# STM32F405 register map
STM32F405 (Cortex-M4F): RCC, GPIOA and USART1
CPU: CM4, FPU
Registers are 32-bit, access not given, no defined reset value unless marked. A register's access mark holds for its fields unless they carry their own. Offsets are from the block's base; lines under a group give offsets from that group; [hi:lo] are bit positions; {n}, {i} and the like mark numbered series; 'fields as' and 'values as' point back to an identical list; <NAME> marks a mode.

## Memory map
0x40011000 USART1 — Universal synchronous asynchronous receiver transmitter
0x40020000 GPIOA — General-purpose I/Os
0x40023800 RCC — Reset and clock control

## Interrupts
37 USART1 — USART1 global interrupt

## RCC — Reset and clock control
Base 0x40023800
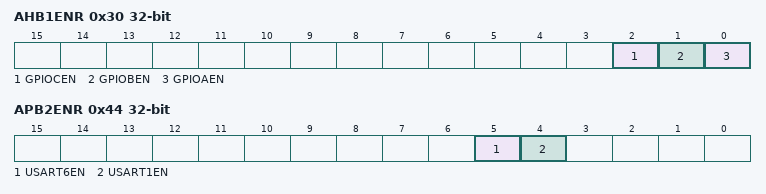
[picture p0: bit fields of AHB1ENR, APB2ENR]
0x30 AHB1ENR — AHB1 peripheral clock enable register
  [2] GPIOCEN — IO port C clock enable
  [1] GPIOBEN — IO port B clock enable
  [0] GPIOAEN — IO port A clock enable
0x44 APB2ENR — APB2 peripheral clock enable register
  [5] USART6EN — USART6 clock enable
  [4] USART1EN — USART1 clock enable

## GPIOA — General-purpose I/Os
Base 0x40020000
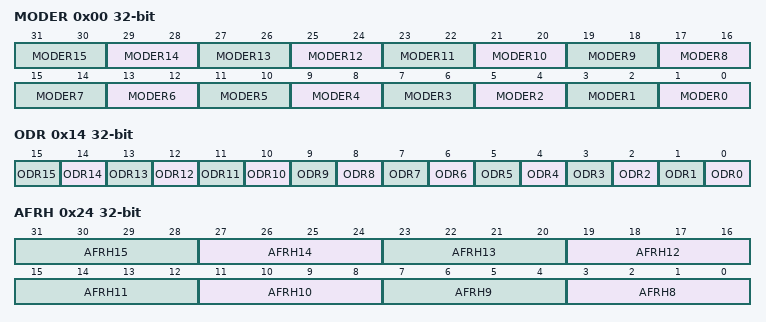
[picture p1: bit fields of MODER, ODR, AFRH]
0x00 MODER — GPIO port mode register: 0 input, 1 output, 2 alternate function, 3 analog
  [2n+1:2n] MODER{n} (n=0..15) — Port x configuration
0x14 ODR — GPIO port output data register
  [n] ODR{n} (n=0..15) — Port output data
0x24 AFRH — GPIO alternate function high register (pins 8-15)
  [4n-29:4n-32] AFRH{n} (n=8..15) — Alternate function for pin x

## USART1 — Universal synchronous asynchronous receiver transmitter
Base 0x40011000
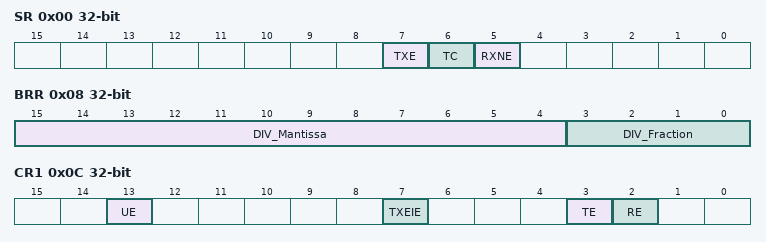
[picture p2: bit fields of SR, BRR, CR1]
0x00 SR — Status register
  [7] TXE — Transmit data register empty
  [6] TC — Transmission complete
  [5] RXNE — Read data register not empty
0x04 DR — Data register
  [8:0] DR — Data value
0x08 BRR — Baud rate register: the bus clock divided by the baud rate
  [15:4] DIV_Mantissa — mantissa of USARTDIV
  [3:0] DIV_Fraction — fraction of USARTDIV
0x0C CR1 — Control register 1
  [13] UE — USART enable
  [7] TXEIE — TXE interrupt enable
  [3] TE — Transmitter enable
  [2] RE — Receiver enable
